# ESP32-P4 register map
Vendor: ESPRESSIF SYSTEMS (SHANGHAI) CO., LTD.; Series: ESP32 P-Series; File version: 3
CPU: RV32IMAFC r0p0, little endian, no MPU, FPU, 0 interrupt priority bits
Address unit: 32 bits
Registers are 32-bit, read-write, reset 0x0 unless marked. A register's access mark holds for its fields unless they carry their own. Offsets are from the block's base; [hi:lo] are bit positions; {n}, {i} and the like mark numbered series; 'fields as' and 'values as' point back to an identical list.

## LP_ANA — LP_ANA_PERI Peripheral
Base 0x50113000
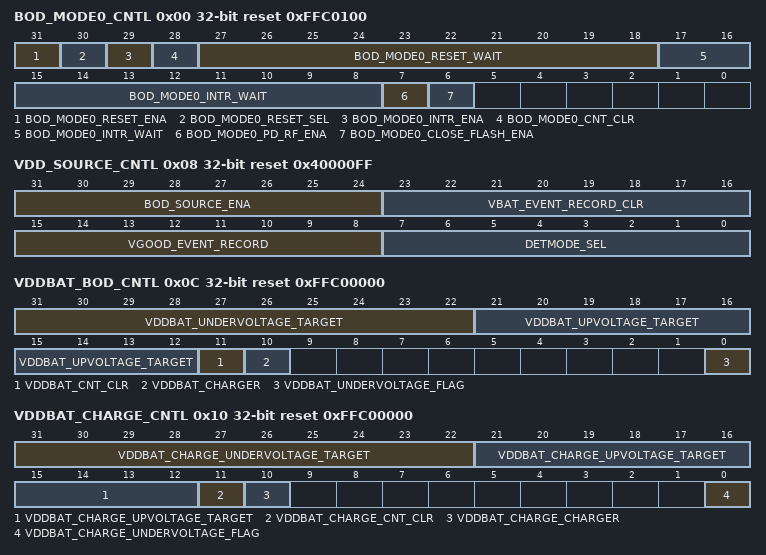
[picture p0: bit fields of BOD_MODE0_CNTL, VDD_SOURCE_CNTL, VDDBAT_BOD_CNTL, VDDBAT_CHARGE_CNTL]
0x00 BOD_MODE0_CNTL reset 0xFFC0100 — need_des
  [31] BOD_MODE0_RESET_ENA — need_des
  [30] BOD_MODE0_RESET_SEL — need_des
  [29] BOD_MODE0_INTR_ENA — need_des
  [28] BOD_MODE0_CNT_CLR — need_des
  [27:18] BOD_MODE0_RESET_WAIT — need_des
  [17:8] BOD_MODE0_INTR_WAIT — need_des
  [7] BOD_MODE0_PD_RF_ENA — need_des
  [6] BOD_MODE0_CLOSE_FLASH_ENA — need_des
0x04 BOD_MODE1_CNTL — need_des
  [31] BOD_MODE1_RESET_ENA
0x08 VDD_SOURCE_CNTL access per field reset 0x40000FF — need_des
  [31:24] BOD_SOURCE_ENA rw — need_des
  [23:16] VBAT_EVENT_RECORD_CLR wo — need_des
  [15:8] VGOOD_EVENT_RECORD ro — need_des
  [7:0] DETMODE_SEL rw — need_des
0x0C VDDBAT_BOD_CNTL access per field reset 0xFFC00000 — need_des
  [31:22] VDDBAT_UNDERVOLTAGE_TARGET rw — need_des
  [21:12] VDDBAT_UPVOLTAGE_TARGET rw — need_des
  [11] VDDBAT_CNT_CLR rw — need_des
  [10] VDDBAT_CHARGER rw — need_des
  [0] VDDBAT_UNDERVOLTAGE_FLAG ro — need_des
0x10 VDDBAT_CHARGE_CNTL access per field reset 0xFFC00000 — need_des
  [31:22] VDDBAT_CHARGE_UNDERVOLTAGE_TARGET rw — need_des
  [21:12] VDDBAT_CHARGE_UPVOLTAGE_TARGET rw — need_des
  [11] VDDBAT_CHARGE_CNT_CLR rw — need_des
  [10] VDDBAT_CHARGE_CHARGER rw — need_des
  [0] VDDBAT_CHARGE_UNDERVOLTAGE_FLAG ro — need_des
0x14 CK_GLITCH_CNTL — need_des
  [31] CK_GLITCH_RESET_ENA
0x18 PG_GLITCH_CNTL — need_des
  [31] POWER_GLITCH_RESET_ENA
0x1C FIB_ENABLE reset 0xFFFFFFFF — need_des
  [31:0] ANA_FIB_ENA
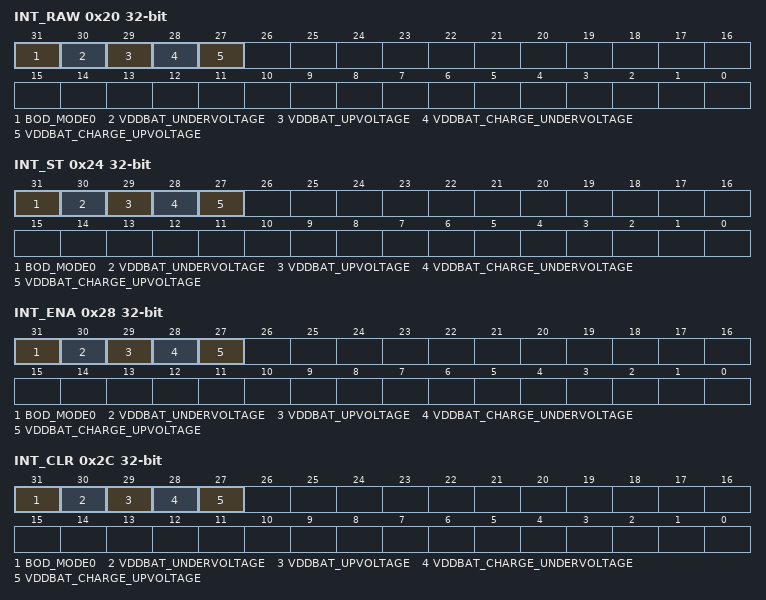
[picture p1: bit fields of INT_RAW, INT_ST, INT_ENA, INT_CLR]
0x20 INT_RAW — need_des
  [31] BOD_MODE0 — need_des
  [30] VDDBAT_UNDERVOLTAGE — need_des
  [29] VDDBAT_UPVOLTAGE — need_des
  [28] VDDBAT_CHARGE_UNDERVOLTAGE — need_des
  [27] VDDBAT_CHARGE_UPVOLTAGE — need_des
0x24 INT_ST ro — need_des
  fields as INT_RAW
0x28 INT_ENA — need_des
  fields as INT_RAW
0x2C INT_CLR wo — need_des
  [31] BOD_MODE0 write-1-clears — need_des
  [30] VDDBAT_UNDERVOLTAGE write-1-clears — need_des
  [29] VDDBAT_UPVOLTAGE write-1-clears — need_des
  [28] VDDBAT_CHARGE_UNDERVOLTAGE write-1-clears — need_des
  [27] VDDBAT_CHARGE_UPVOLTAGE write-1-clears — need_des
0x30 LP_INT_RAW — need_des
  [31] BOD_MODE0
0x34 LP_INT_ST ro — need_des
  [31] BOD_MODE0
0x38 LP_INT_ENA — need_des
  [31] BOD_MODE0
0x3C LP_INT_CLR wo — need_des
  [31] BOD_MODE0 write-1-clears
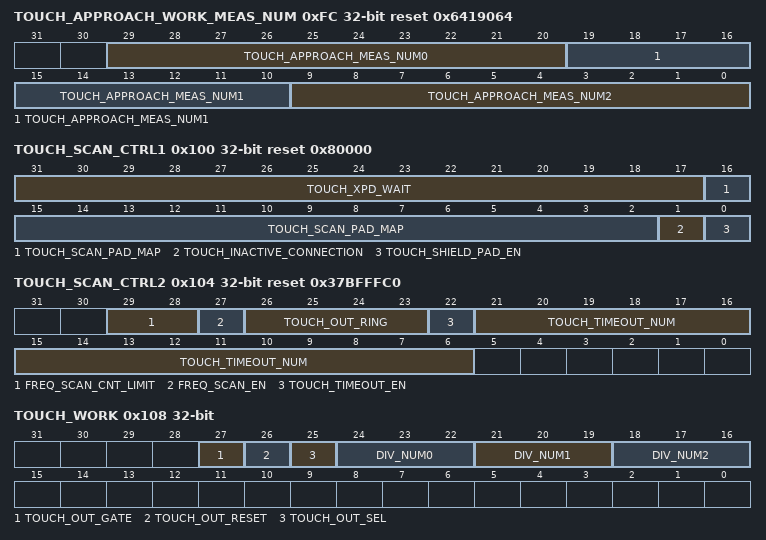
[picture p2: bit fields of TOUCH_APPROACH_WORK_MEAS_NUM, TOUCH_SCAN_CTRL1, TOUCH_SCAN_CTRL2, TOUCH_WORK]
0xFC TOUCH_APPROACH_WORK_MEAS_NUM reset 0x6419064 — need_des
  [29:20] TOUCH_APPROACH_MEAS_NUM0 — need_des
  [19:10] TOUCH_APPROACH_MEAS_NUM1 — need_des
  [9:0] TOUCH_APPROACH_MEAS_NUM2 — need_des
0x100 TOUCH_SCAN_CTRL1 reset 0x80000 — need_des
  [31:17] TOUCH_XPD_WAIT — need_des
  [16:2] TOUCH_SCAN_PAD_MAP — need_des
  [1] TOUCH_INACTIVE_CONNECTION — need_des
  [0] TOUCH_SHIELD_PAD_EN — need_des
0x104 TOUCH_SCAN_CTRL2 reset 0x37BFFFC0 — need_des
  [29:28] FREQ_SCAN_CNT_LIMIT — need_des
  [27] FREQ_SCAN_EN — need_des
  [26:23] TOUCH_OUT_RING — need_des
  [22] TOUCH_TIMEOUT_EN — need_des
  [21:6] TOUCH_TIMEOUT_NUM — need_des
0x108 TOUCH_WORK access per field — need_des
  [27] TOUCH_OUT_GATE rw — need_des
  [26] TOUCH_OUT_RESET wo — need_des
  [25] TOUCH_OUT_SEL rw — need_des
  [24:22] DIV_NUM0 rw — need_des
  [21:19] DIV_NUM1 rw — need_des
  [18:16] DIV_NUM2 rw — need_des
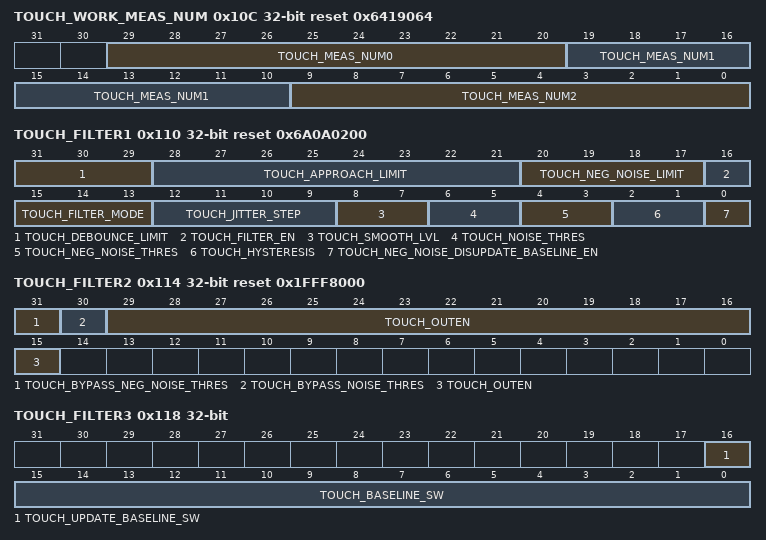
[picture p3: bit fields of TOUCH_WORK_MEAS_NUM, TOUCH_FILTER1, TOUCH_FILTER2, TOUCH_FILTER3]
0x10C TOUCH_WORK_MEAS_NUM reset 0x6419064 — need_des
  [29:20] TOUCH_MEAS_NUM0 — need_des
  [19:10] TOUCH_MEAS_NUM1 — need_des
  [9:0] TOUCH_MEAS_NUM2 — need_des
0x110 TOUCH_FILTER1 reset 0x6A0A0200 — need_des
  [31:29] TOUCH_DEBOUNCE_LIMIT — need_des
  [28:21] TOUCH_APPROACH_LIMIT — need_des
  [20:17] TOUCH_NEG_NOISE_LIMIT — need_des
  [16] TOUCH_FILTER_EN — need_des
  [15:13] TOUCH_FILTER_MODE — need_des
  [12:9] TOUCH_JITTER_STEP — need_des
  [8:7] TOUCH_SMOOTH_LVL — need_des
  [6:5] TOUCH_NOISE_THRES — need_des
  [4:3] TOUCH_NEG_NOISE_THRES — need_des
  [2:1] TOUCH_HYSTERESIS — need_des
  [0] TOUCH_NEG_NOISE_DISUPDATE_BASELINE_EN — Reserved
0x114 TOUCH_FILTER2 reset 0x1FFF8000 — need_des
  [31] TOUCH_BYPASS_NEG_NOISE_THRES — need_des
  [30] TOUCH_BYPASS_NOISE_THRES — need_des
  [29:15] TOUCH_OUTEN — need_des
0x118 TOUCH_FILTER3 access per field — need_des
  [16] TOUCH_UPDATE_BASELINE_SW wo — need_des
  [15:0] TOUCH_BASELINE_SW rw — need_des
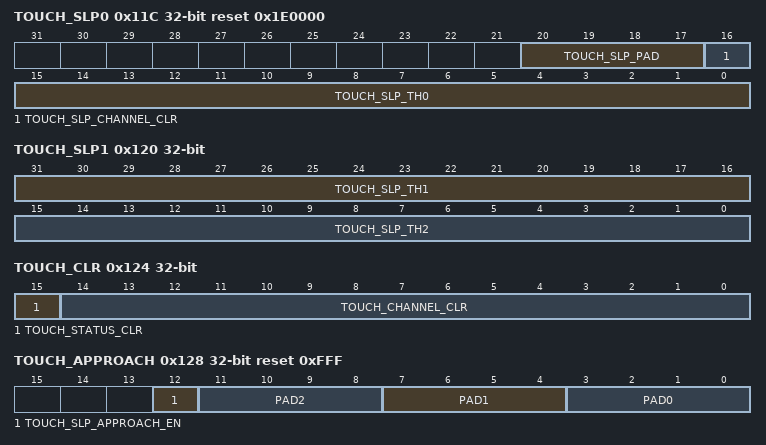
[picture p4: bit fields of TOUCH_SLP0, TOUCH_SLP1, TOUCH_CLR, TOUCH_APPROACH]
0x11C TOUCH_SLP0 access per field reset 0x1E0000 — need_des
  [20:17] TOUCH_SLP_PAD rw — need_des
  [16] TOUCH_SLP_CHANNEL_CLR wo — need_des
  [15:0] TOUCH_SLP_TH0 rw — need_des
0x120 TOUCH_SLP1 — need_des
  [31:16] TOUCH_SLP_TH1 — need_des
  [15:0] TOUCH_SLP_TH2 — need_des
0x124 TOUCH_CLR wo — need_des
  [15] TOUCH_STATUS_CLR — need_des
  [14:0] TOUCH_CHANNEL_CLR — need_des
0x128 TOUCH_APPROACH reset 0xFFF — need_des
  [12] TOUCH_SLP_APPROACH_EN — need_des
  [11:8] PAD2 — need_des
  [7:4] PAD1 — need_des
  [3:0] PAD0 — need_des
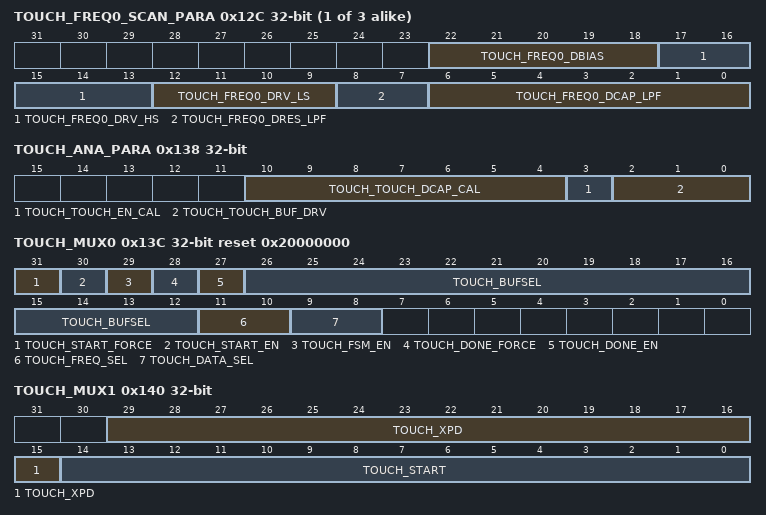
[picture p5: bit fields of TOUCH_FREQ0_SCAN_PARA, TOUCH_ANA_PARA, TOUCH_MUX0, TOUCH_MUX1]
{0x12C+4i} TOUCH_FREQ{i}_SCAN_PARA (i=0..2) — need_des
  [22:18] TOUCH_FREQ{i}_DBIAS — need_des
  [17:13] TOUCH_FREQ{i}_DRV_HS — need_des
  [12:9] TOUCH_FREQ{i}_DRV_LS — need_des
  [8:7] TOUCH_FREQ{i}_DRES_LPF — need_des
  [6:0] TOUCH_FREQ{i}_DCAP_LPF — need_des
0x138 TOUCH_ANA_PARA — need_des
  [10:4] TOUCH_TOUCH_DCAP_CAL — need_des
  [3] TOUCH_TOUCH_EN_CAL — need_des
  [2:0] TOUCH_TOUCH_BUF_DRV — need_des
0x13C TOUCH_MUX0 reset 0x20000000 — need_des
  [31] TOUCH_START_FORCE — need_des
  [30] TOUCH_START_EN — need_des
  [29] TOUCH_FSM_EN — need_des
  [28] TOUCH_DONE_FORCE — need_des
  [27] TOUCH_DONE_EN — need_des
  [26:12] TOUCH_BUFSEL — need_des
  [11:10] TOUCH_FREQ_SEL — need_des
  [9:8] TOUCH_DATA_SEL — need_des
0x140 TOUCH_MUX1 — need_des
  [29:15] TOUCH_XPD — need_des
  [14:0] TOUCH_START — need_des
{0x144+0xC*i} TOUCH_PAD{i}_TH0 (i=0..14) — need_des
  [31:16] TOUCH_PAD{i}_TH0 — Reserved
{0x148+0xC*i} TOUCH_PAD{i}_TH1 (i=0..14) — need_des
  [31:16] TOUCH_PAD{i}_TH1 — Reserved
{0x14C+0xC*i} TOUCH_PAD{i}_TH2 (i=0..14) — need_des
  [31:16] TOUCH_PAD{i}_TH2 — Reserved
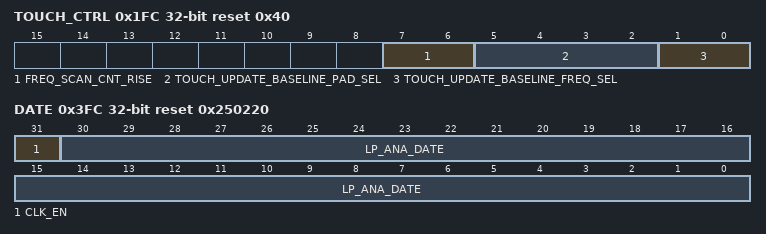
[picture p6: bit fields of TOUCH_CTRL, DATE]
0x1FC TOUCH_CTRL reset 0x40 — Touch Control Register
  [7:6] FREQ_SCAN_CNT_RISE — Configure the number of hit frequency points that need to be determined for touch in frequency hopping mode.
  [5:2] TOUCH_UPDATE_BASELINE_PAD_SEL — Configure the channel for software to update the baseline.
  [1:0] TOUCH_UPDATE_BASELINE_FREQ_SEL — Configure the frequency point for software to update the baseline
0x3FC DATE reset 0x250220 — need_des
  [31] CLK_EN — need_des
  [30:0] LP_ANA_DATE — need_des
